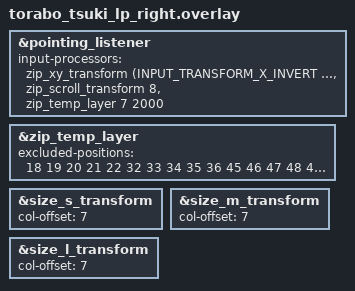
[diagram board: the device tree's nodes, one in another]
#include "torabo_tsuki_lp.dtsi"
#include <input/processors.dtsi>
#include <dt-bindings/zmk/input_transform.h>

/* 1. ポインティングリスナーの設定（元の安全な状態に戻す） */
&pointing_listener {
    input-processors = 
        /* XY反転設定 */
        <&zip_xy_transform (INPUT_TRANSFORM_X_INVERT | INPUT_TRANSFORM_Y_INVERT)>,
        
        /* スクロール変換レイヤー（レイヤー8） */
        <&zip_scroll_transform  8>,

        /* オートマウス(レイヤー7)設定 */
        <&zip_temp_layer 7 2000>;
};

/* 2. オートマウス除外キー設定（ここを限界まで広げて誤爆を殺す） */
&zip_temp_layer {
    /* 
     * 【重要】ここに登録されているキーを「押している間」はオートマウスが完全に眠ります。
     * 現在の番号（18〜50付近）に加えて、キーマップ上の左手側・右手側の
     * すべてのアルファベットキー、スペースキー、エンターキー、バックスペースなどの
     * インデックス番号を調べて、スペース区切りでここにすべて書き足してください。
     */
    excluded-positions = <
        18 19 20 21 22
        32 33 34 35 36
        45 46 47 48 49 50
        63
        /* ⬇️ ここに他のすべての文字キーの番号を半角スペース空けで追加します ⬇️ */
        
    >;
};

/* 3. 既存のレイアウト変換設定（維持） */
&size_s_transform { col-offset = <7>; };
&size_m_transform { col-offset = <7>; };
&size_l_transform { col-offset = <7>; };
